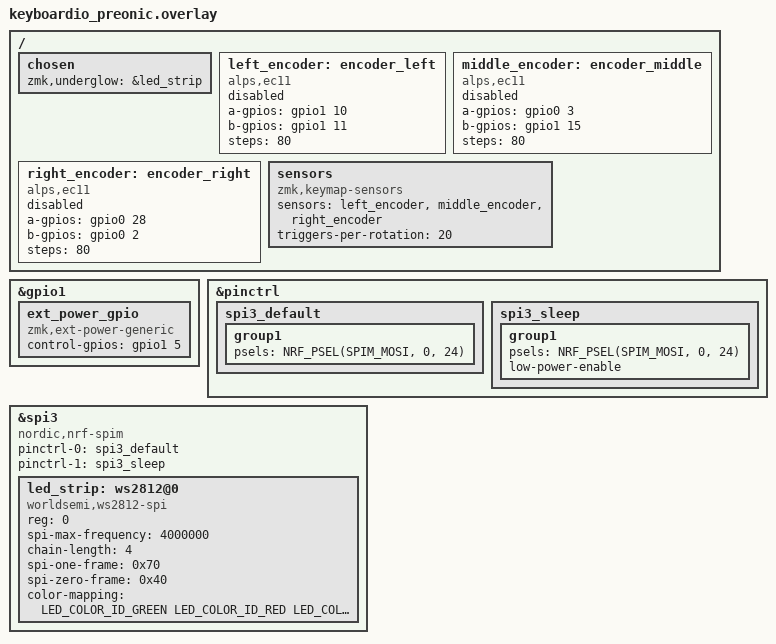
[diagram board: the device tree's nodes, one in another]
#include <dt-bindings/led/led.h>
/ {
    chosen {
        zmk,underglow = &led_strip;
    };
    left_encoder: encoder_left {
        compatible = "alps,ec11";
        //flipped the pins because they are reversed (untested)
        a-gpios = <&gpio1 10 (GPIO_ACTIVE_HIGH | GPIO_PULL_UP)>;
        b-gpios = <&gpio1 11 (GPIO_ACTIVE_HIGH | GPIO_PULL_UP)>;
        steps = <80>;
        status = "disabled";
    };
    middle_encoder: encoder_middle {
        compatible = "alps,ec11";
        //flipped the pins because they are reversed (untested)
        a-gpios = <&gpio0 3 (GPIO_ACTIVE_HIGH | GPIO_PULL_UP)>;
        b-gpios = <&gpio1 15 (GPIO_ACTIVE_HIGH | GPIO_PULL_UP)>;
        steps = <80>;
        status = "disabled";
    };

    right_encoder: encoder_right {
        compatible = "alps,ec11";
        //flipped the pins because they are reversed
        a-gpios = <&gpio0 28 (GPIO_ACTIVE_HIGH | GPIO_PULL_UP)>;
        b-gpios = <&gpio0 2 (GPIO_ACTIVE_HIGH | GPIO_PULL_UP)>;
        steps = <80>;
        status = "disabled";
    };

    sensors: sensors {
        compatible = "zmk,keymap-sensors";
        sensors = <&left_encoder &middle_encoder &right_encoder>;
        triggers-per-rotation = <20>;
    };
};
&gpio1 {
    ext_power_gpio: ext_power_gpio {
        compatible = "zmk,ext-power-generic";
        status = "okay";
        control-gpios = <&gpio1 5 GPIO_ACTIVE_HIGH>;
    };
};




&pinctrl {
    spi3_default: spi3_default {
        group1 {
            psels = <NRF_PSEL(SPIM_MOSI, 0, 24)>;
        };
    };

    spi3_sleep: spi3_sleep {
        group1 {
            psels = <NRF_PSEL(SPIM_MOSI, 0, 24)>;
            low-power-enable;
        };
    };
};

&spi3 {
    compatible = "nordic,nrf-spim";
    status = "okay";

    pinctrl-0 = <&spi3_default>;
    pinctrl-1 = <&spi3_sleep>;
    pinctrl-names = "default", "sleep";

    led_strip: ws2812@0 {
        compatible = "worldsemi,ws2812-spi";

        /* SPI */
        reg = <0>; /* ignored, but necessary for SPI bindings */
        spi-max-frequency = <4000000>;

        /* WS2812 */
        chain-length = <4>; /* number of LEDs */
        spi-one-frame = <0x70>;
        spi-zero-frame = <0x40>;
        color-mapping = <LED_COLOR_ID_GREEN
                         LED_COLOR_ID_RED
                         LED_COLOR_ID_BLUE>;
    };
};

